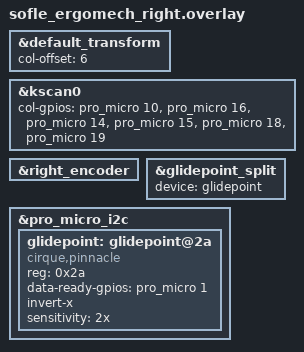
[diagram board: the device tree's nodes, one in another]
/*
 * Copyright (c) 2020 Ryan Cross
 *
 * SPDX-License-Identifier: MIT
 */

#include "sofle_ergomech.dtsi"

&default_transform {
    col-offset = <6>;
};

&kscan0 {
    col-gpios
        = <&pro_micro 10 GPIO_ACTIVE_HIGH>
        , <&pro_micro 16 GPIO_ACTIVE_HIGH>
        , <&pro_micro 14 GPIO_ACTIVE_HIGH>
        , <&pro_micro 15 GPIO_ACTIVE_HIGH>
        , <&pro_micro 18 GPIO_ACTIVE_HIGH>
        , <&pro_micro 19 GPIO_ACTIVE_HIGH>
        ;
};

&right_encoder {
    status = "okay";
};

// Link physical device to the split node defined in dtsi
&glidepoint_split {
    device = <&glidepoint>;
};

// Define and enable physical device node
&pro_micro_i2c {
    status = "okay"; // Ensure I2C bus is enabled

    glidepoint: glidepoint@2a {
        compatible = "cirque,pinnacle";
        reg = <0x2a>;
        status = "okay";
        data-ready-gpios = <&pro_micro 1 GPIO_ACTIVE_HIGH>;
        invert-x;
        sensitivity = "2x";
    };
};
